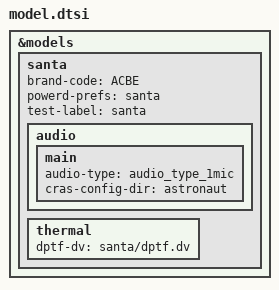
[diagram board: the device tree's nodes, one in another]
/*
 * Copyright 2017 The Chromium OS Authors. All rights reserved.
 *
 * Use of this source code is governed by a BSD-style license that can be
 * found in the LICENSE file.
 */

&models {
	santa: santa {
		brand-code = "ACBE";
		powerd-prefs = "santa";
		test-label = "santa";
		audio {
			main {
				audio-type = <&audio_type_1mic>;
				cras-config-dir = "astronaut";
			};
		};
		thermal {
			/* Could also point to astronaut/dptf.dv */
			dptf-dv = "santa/dptf.dv";
		};
	};
};
